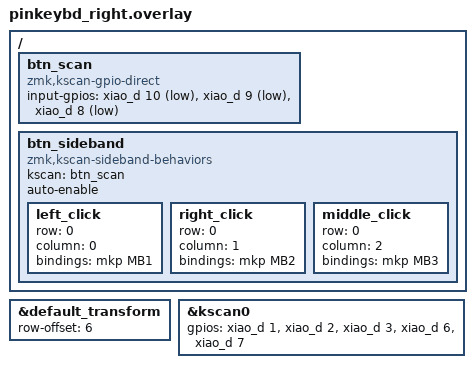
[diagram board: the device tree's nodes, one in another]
#include "pinkeybd.dtsi"
#include <dt-bindings/zmk/matrix_transform.h>
#include <physical_layouts.dtsi>
#include <dt-bindings/input/input-event-codes.h>
#include <input/processors.dtsi>
#include <dt-bindings/zmk/pointing.h>

// The matrix transform for this board is 6 columns over because the left half is 5 columns wide according to the matrix.
&default_transform {
    row-offset = <6>;
};


/ {

    btn_scan: btn_scan {
        compatible = "zmk,kscan-gpio-direct";
        input-gpios =
            <&xiao_d 10 (GPIO_ACTIVE_LOW | GPIO_PULL_UP)>,
            <&xiao_d 9 (GPIO_ACTIVE_LOW | GPIO_PULL_UP)>,
            <&xiao_d 8 (GPIO_ACTIVE_LOW | GPIO_PULL_UP)>;
    };

    btn_sideband: btn_sideband {
        compatible = "zmk,kscan-sideband-behaviors";
        kscan = <&btn_scan>;
        auto-enable;
        left_click {
            row = <0>;
            column = <0>;
            bindings = <&mkp MB1>;
        };
        right_click {
            row = <0>;
            column = <1>;
            bindings = <&mkp MB2>;
        };
        middle_click {
            row = <0>;
            column = <2>;
            bindings = <&mkp MB3>;
        };
    };
};

&kscan0 {
    gpios
        = <&xiao_d 1 GPIO_ACTIVE_HIGH>
        , <&xiao_d 2 GPIO_ACTIVE_HIGH>
        , <&xiao_d 3 GPIO_ACTIVE_HIGH>
        , <&xiao_d 6 GPIO_ACTIVE_HIGH>
        , <&xiao_d 7 GPIO_ACTIVE_HIGH>
        ;
};
